# D1H.pdf register map
Vendor: Allwinner; Series: D1H.pdf; File version: 0.1
CPU: XuanTie C906 RISC-V CPU 0, little endian, MPU, FPU, double-precision FPU, 0 interrupt priority bits
Registers are 32-bit, read-write, reset 0x0 unless marked. A register's access mark holds for its fields unless they carry their own. Offsets are from the block's base; lines under a group give offsets from that group; [hi:lo] are bit positions; {n}, {i} and the like mark numbered series; 'fields as' and 'values as' point back to an identical list; <NAME> marks a mode.

## Memory map
0x01701000 DSP_MSGBOX
0x02000000 GPIO
0x02000C00 PWM
0x02001000 CCU
0x02003000 CIR_TX
0x02008000 LEDC
0x02009000 GPADC
0x02009400 THS
0x02009800 LRADC
0x02009C00 TPADC
0x02010000 IOMMU
0x02030000 Audio_Codec
0x02031000 DMIC
0x02032000 I2S/PCM0
0x02033000 I2S/PCM1
0x02034000 I2S/PCM2
0x02036000 OWA
0x02050000 Timer
0x02500000 UART0
0x02500400 UART1
0x02500800 UART2
0x02500C00 UART3
0x02501000 UART4
0x02501400 UART5
0x02502000 TWI0
0x02502400 TWI1
0x02502800 TWI2
0x02502C00 TWI3
0x03000000 SYS_CFG
0x03002000 DMAC
0x03005000 Spinlock
0x03008000 HSTimer
0x03040000 CE_NS
0x04020000 SMHC0
0x04021000 SMHC1
0x04022000 SMHC2
0x04026000 SPI_DBI
0x04200000 USB1
0x04500000 EMAC
0x05461000 TCON_LCD0
0x05470000 TCON_TV0
0x05600000 TVE_TOP
0x05604000 TVE
0x05800000 CSIC_CCU
0x05800800 CSIC_TOP
0x05801000 CSIC_PARSER0
0x05809000 CSIC_DMA0
0x05809200 CSIC_DMA1
0x05C00000 TVD_TOP
0x05C01000 TVD0
0x06010000 RISCV_CFG
0x0601F000 RISC-V_MSGBOX
0x07040000 CIR_RX
0x07090000 RTC
0x10000000 RISCV_PLIC

## CSIC_CCU
Base 0x05800000
0x00 CCU_CLK_MODE_REG reset 0x80000000 — CCU Clock Mode Register
  [31] CCU_CLK_GATING_DISABLE — 0: CCU Clock Gating Registers(0x0004~0x0010) effect 1: CCU Clock Gating Registers(0x0004~0x0010) not effect
    0=CCU_Clock_Gating_Registers_openingparen_0x0004_tilde_0x0010_closingparen__effect (CCU Clock Gating Registers(0x0004~0x0010) effect); 1=CCU_Clock_Gating_Registers_openingparen_0x0004_tilde_0x0010_closingparen__not_effect (CCU Clock Gating Registers(0x0004~0x0010) not effect)
0x04 CCU_PARSER_CLK_EN_REG — CCU Parser Clock Enable Register
  [0] MCSI_PARSER0_CLK_ENABLE — 0: CSI Parser0 clock disable 1: CSI Parser0 clock enable
    0=CSI_Parser0_clock_disable; 1=CSI_Parser0_clock_enable
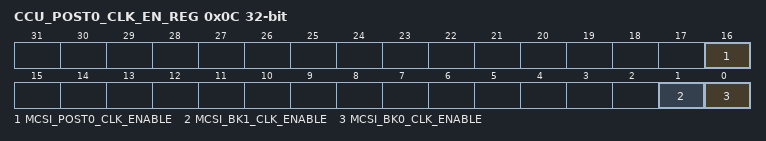
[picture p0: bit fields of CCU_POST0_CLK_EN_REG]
0x0C CCU_POST0_CLK_EN_REG — CCU Post0 Clock Enable Register
  [16] MCSI_POST0_CLK_ENABLE — 0: POST0 clock disable 1: POST0 clock enable
    0=POST0_clock_disable; 1=POST0_clock_enable
  [1] MCSI_BK1_CLK_ENABLE — 0: BK1 clock disable 1: BK1 clock enable,when MCSI_POST0_CLK_ENABLE is 1
    0=BK1_clock_disable; 1=BK1 clock enable,when MCSI_POST0_CLK_ENABLE is 1
  [0] MCSI_BK0_CLK_ENABLE — 0: BK0 clock disable 1: BK0 clock enable,when MCSI_POST0_CLK_ENABLE is 1
    0=BK0_clock_disable; 1=BK0 clock enable,when MCSI_POST0_CLK_ENABLE is 1

## CSIC_TOP
Base 0x05800800
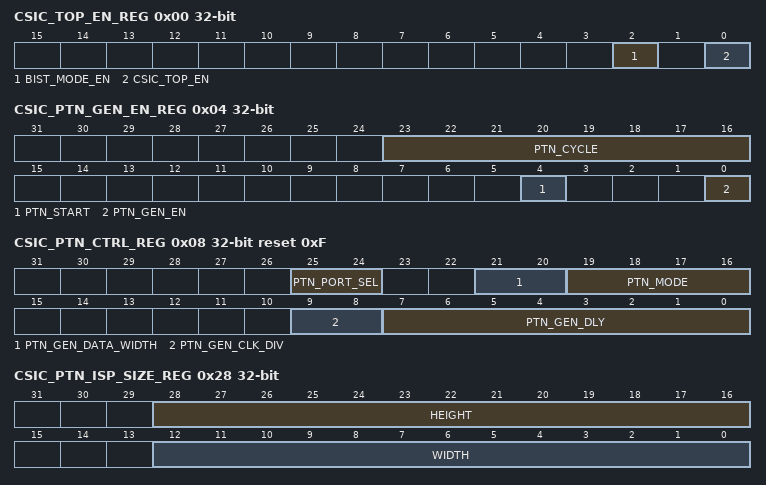
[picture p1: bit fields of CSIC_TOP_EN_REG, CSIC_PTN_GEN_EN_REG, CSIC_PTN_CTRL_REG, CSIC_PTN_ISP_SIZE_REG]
0x00 CSIC_TOP_EN_REG — CSIC TOP Enable Register
  [2] BIST_MODE_EN — 0: Closed 1: EN BIST TEST
    0=Closed; 1=EN (EN BIST TEST)
  [0] CSIC_TOP_EN — 0: Reset and disable the CSIC module 1: Enable the CSIC module
    0=Reset and disable the CSIC module; 1=Enable the CSIC module
0x04 CSIC_PTN_GEN_EN_REG — CSIC Pattern Generation Enable Register
  [23:16] PTN_CYCLE — Pattern generating cycle counter. The pattern in dram will be generated in cycles of PTN_CYCLE+1.
  [4] PTN_START — CSIC Pattern Generating Start 0: Finish other: Start Software write this bit to “1” to start pattern generating from DRAM. When finished, the hardware will clear this bit to “0” automatically. Generating cycles depends on PTN_CYCLE.
    0=Finish other: Start Software write this bit to “1” to start pattern generating from DRAM. When finished, the hardware will clear this bit to “0” automatically. Generating cycles depends on PTN_CYCLE.
  [0] PTN_GEN_EN — Pattern Generation Enable
0x08 CSIC_PTN_CTRL_REG reset 0xF — CSIC Pattern Control Register
  [25:24] PTN_PORT_SEL — Pattern Generator output port selection 010:NCSIC0 others:reserved
  [21:20] PTN_GEN_DATA_WIDTH — 00:8-bit 01:10-bit 10:12-bit 11:reserved
  [19:16] PTN_MODE — Pattern mode selection 0000~0011:reserved 0100:NCSIC YUV 8 bits width 0101:NCSIC YUV 16 bits width 0110:reserved 0111:reserved 1000:BT656 8 bits width 1001:BT656 16 bits width 1010:reserved 1011:reserved 1100:BAYER 12 bits for ISPFE 1101:UYVY422 12 bits for ISPFE 1110:UYVY420 12 bits for ISPFE 1111:reserved
  [9:8] PTN_GEN_CLK_DIV — Packet generator clock divider
  [7:0] PTN_GEN_DLY — Clocks delayed before pattern generating start.
0x20 CSIC_PTN_LEN_REG — CSIC Pattern Generation Length Register
  [31:0] PTN_LEN — The pattern length in byte when generating pattern.
0x24 CSIC_PTN_ADDR_REG — CSIC Pattern Generation Address Register
  [31:0] PTN_ADDR — The pattern DRAM address when generating pattern.
0x28 CSIC_PTN_ISP_SIZE_REG — CSIC Pattern ISP Size Register
  [28:16] HEIGHT — Height Vertical size, only valid for ISP mode pattern generation.
  [12:0] WIDTH — Width Horizontal size, only valid for ISP mode pattern generation.
0xA0 CSIC_DMA0_INPUT_SEL_REG — CSIC DMA0 Input Select Register
  [3:0] DMA0 — Input Select 0000: input from ISP0 CH0 0001: input from ISP0 CH1 0010: input from ISP0 CH2 0011: input from ISP0 CH3 Others: Reserved
    {v}=input_from_ISP0_CH{v} (v=0..3)
0xA4 CSIC_DMA1_INPUT_SEL_REG — CSIC DMA1 Input Select Register
  [3:0] DMA1 — Input Select 0000: input from ISP0 CH0 0001: input from ISP0 CH1 0010: input from ISP0 CH2 0011: input from ISP0 CH3 Others: Reserved
    {v}=input_from_ISP0_CH{v} (v=0..3)
0xDC CSIC_BIST_CS_REG — CSIC BIST CS Register
  [2:0] BIST_CS — 000: Set when BK0 memory bist 001: Set when BK1 memory bist Others: Reserved
    0=Set when BK0 memory bist; 1=Set when BK1 memory bist
0xEC CSIC_BIST_DATA_MASK_REG — CSIC BIST Data Mask Register
  [31:0] BIST_DATA_MASK — BIST Data Mask 0: Unmask 1: Mask
0xF0 CSIC_MBUS_REQ_MAX_REG reset 0xF — CSIC MBUS REQ MAX Register
  [4:0] MCSI_MEM_REQ_MAX — Maximum of request commands for the master granted in MCSI_MEM arbiter is N+1.
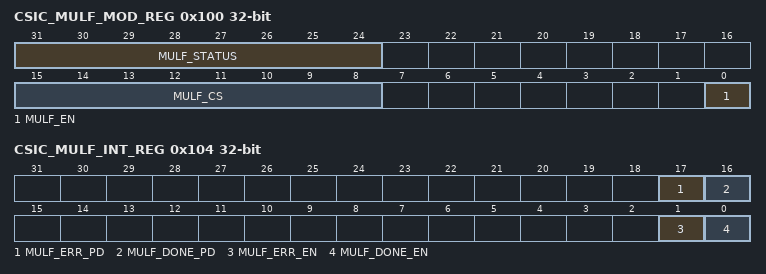
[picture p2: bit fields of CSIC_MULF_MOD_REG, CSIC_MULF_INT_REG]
0x100 CSIC_MULF_MOD_REG — CSIC Multi-Frame Mode Register
  [31:24] MULF_STATUS ro, [15:8] MULF_CS, [0] MULF_EN
0x104 CSIC_MULF_INT_REG — CSIC Multi-Frame Interrupt Register
  [17] MULF_ERR_PD write-1-clears, [16] MULF_DONE_PD write-1-clears, [1] MULF_ERR_EN, [0] MULF_DONE_EN

## Licence text in the file
questionable
